# nrf9230_engb_application register map
Vendor: Nordic Semiconductor; Series: nRF92; File version: 1
CPU: CM33 r0p4, little endian, MPU, FPU, 3 interrupt priority bits, 480 interrupts, 4 SAU regions
Registers are 32-bit, read-write, reset 0x0 unless marked. A register's access mark holds for its fields unless they carry their own. Offsets are from the block's base; [hi:lo] are bit positions; lines under a group give offsets from that group; {n}, {i} and the like mark numbered series.

## GLOBAL_RESETHUB_S — Reset hub
Base 0x5F949000
{0x0+4i} TASKS_RESETDOMAIN[{i}] (i=0..7) wo — Description collection: Reset the domain [n], where n is domain id.
  [0] TASKS_RESETDOMAIN — Reset the domain [n], where n is domain id.
    1=Trigger task
{0x100+4i} EVENTS_DOMAINRESET[{i}] (i=0..7) — Description collection: Domain [n] was reset, where n is domain id.
  [0] EVENTS_DOMAINRESET — Domain [n] was reset, where n is domain id.
    0=NotGenerated (Event not generated); 1=Generated (Event generated)
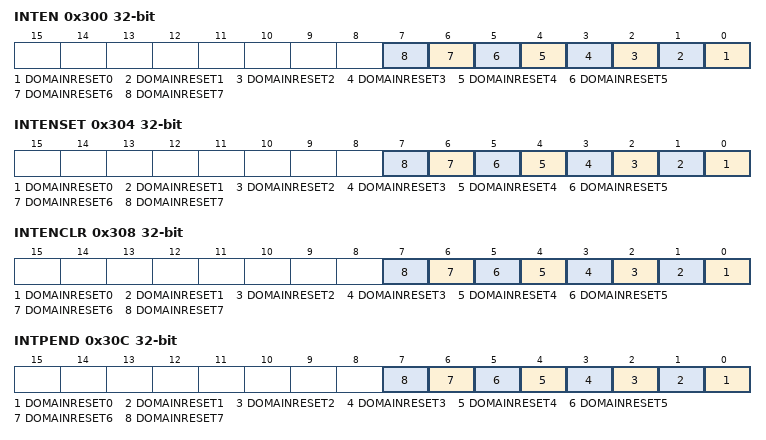
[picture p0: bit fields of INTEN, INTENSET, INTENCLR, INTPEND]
0x300 INTEN — Enable or disable interrupt
  [all] fields
    0=Disabled; 1=Enabled
  [n] DOMAINRESET{n} (n=0..7) — Enable or disable interrupt for event DOMAINRESET[{n}]
0x304 INTENSET — Enable interrupt
  [all] fields
    on read: 0=Disabled (Read: Disabled); 1=Enabled (Read: Enabled) | on write: 1=Set (Enable)
  [n] DOMAINRESET{n} (n=0..7) — Write '1' to enable interrupt for event DOMAINRESET[{n}]
0x308 INTENCLR — Disable interrupt
  [all] fields
    on read: 0=Disabled (Read: Disabled); 1=Enabled (Read: Enabled) | on write: 1=Clear (Disable)
  [n] DOMAINRESET{n} (n=0..7) — Write '1' to disable interrupt for event DOMAINRESET[{n}]
0x30C INTPEND ro — Pending interrupts
  [all] fields
    on read: 0=NotPending (Read: Not pending); 1=Pending (Read: Pending)
  [n] DOMAINRESET{n} (n=0..7) — Read pending status of interrupt for event DOMAINRESET[{n}]
0x400 RESETREAS group — Unspecified
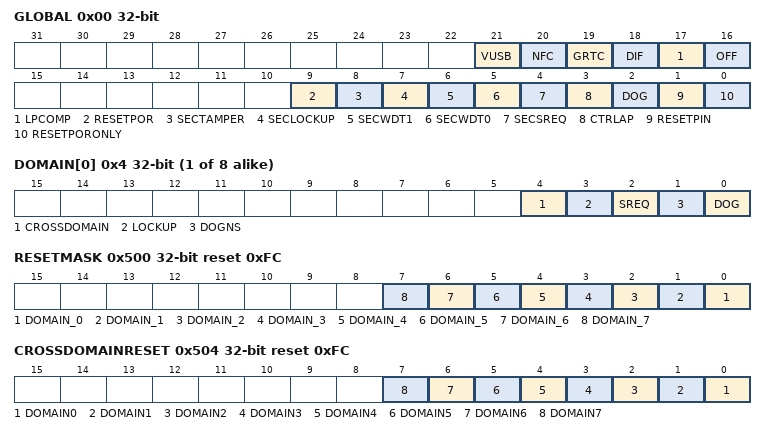
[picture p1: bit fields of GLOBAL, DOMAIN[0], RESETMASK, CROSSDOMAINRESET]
  0x00 GLOBAL write-1-clears — Global reset reason.
    [all] fields
      0=NotDetected; 1=Detected
    [21] VUSB — Reset after wakeup from System OFF mode due to VBUS rising into valid range.
    [20] NFC — Reset due to wakeup from System OFF mode when wakeup is triggered by NFC field detection in sense mode.
    [19] GRTC — Reset due to wakeup from System OFF mode when wakeup is triggered by GRTC interrupt.
    [18] DIF — Reset due to wakeup from System OFF mode when wakeup is triggered by entering the debug interface mode.
    [17] LPCOMP — Reset due to wakeup from System OFF mode when wakeup is triggered by LPCOMP (Low Power Comparator).
    [16] OFF — Reset due to wakeup from System OFF mode when wakeup is triggered by DETECT signal from GPIO.
    [9] RESETPOR — Reset from power on reset (reset reason other than POR or BOR).
    [8] SECTAMPER — Reset due to secure domain tamper detected
    [7] SECLOCKUP — Reset due to secure domain lockup.
    [6] SECWDT1 — Reset due to the second instance of watchdog timer in secure domain detected.
    [5] SECWDT0 — Reset due to the first instance of watchdog timer in secure domain detected.
    [4] SECSREQ — Reset due to secure domain system reset request.
    [3] CTRLAP — Reset from CTRL-AP detected.
    [2] DOG — Reset from the SysCtrl watchdog timer detected.
    [1] RESETPIN — Reset from pin reset detected.
    [0] RESETPORONLY — Reset from power on reset (reset reason POR or BOR).
  {0x4+4j} DOMAIN[{j}] (j=0..7) write-1-clears — Description collection: Reset reason for the domain[n], where n is domain id.
    [all] fields
      0=NotDetected; 1=Detected
    [4] CROSSDOMAIN — Reset due to cross domain reset source.
    [3] LOCKUP — Reset from local CPU lockup detected
    [2] SREQ — Reset from the local soft reset request detected.
    [1] DOGNS — Reset from the local non-secure watchdog timer detected
    [0] DOG — Reset from the local watchdog timer detected
0x500 RESETMASK reset 0xFC — Mask the reset request for a domain by itself.
  [all] fields
    0=Mask the reset request; 1=Unmask the reset request
  [n] DOMAIN_{n} (n=0..7) — Mask the reset request for the domain[{n}], where [{n}] is domain id.
0x504 CROSSDOMAINRESET reset 0xFC — Enable cross domain resets.
  [all] fields
    0=Disabled (Cross domain reset disabled); 1=Enabled (Cross domain reset enabled)
  [n] DOMAIN{n} (n=0..7) — Cross domain reset enable for DOMAIN[{n}], where [{n}] is domain id.
0x508 GPREGRET — General purpose retention register.
  [7:0] GPREGRET
